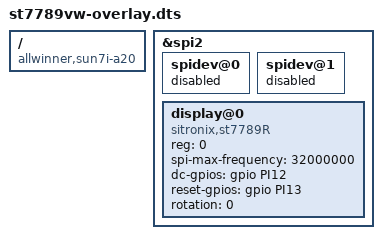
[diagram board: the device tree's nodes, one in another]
/dts-v1/;
/plugin/;

/ {
	compatible = "allwinner,sun7i-a20";

	fragment@0 {
		target = <&spi2>;
		__overlay__ {
			status = "okay";

			spidev@0{
				status = "disabled";
			};

			spidev@1{
				status = "disabled";
			};
		};
	};

	fragment@1 {
		target = <&spi2>;
		__overlay__ {
			/* needed to avoid dtc warning */
			#address-cells = <1>;
			#size-cells = <0>;

			display@0{
                compatible = "sitronix,st7789R";
                reg = <0>;
                spi-max-frequency = <32000000>;
                dc-gpios = <&gpio PI12 GPIO_ACTIVE_HIGH>;
                reset-gpios = <&gpio PI13 GPIO_ACTIVE_HIGH>;
                rotation = <0>;
	        };


		};
	};

	__overrides__ {
		speed =    <&keidei>, "spi-max-frequency:0";
		rotation = <&keidei>, "rotation:0";
	};
};
